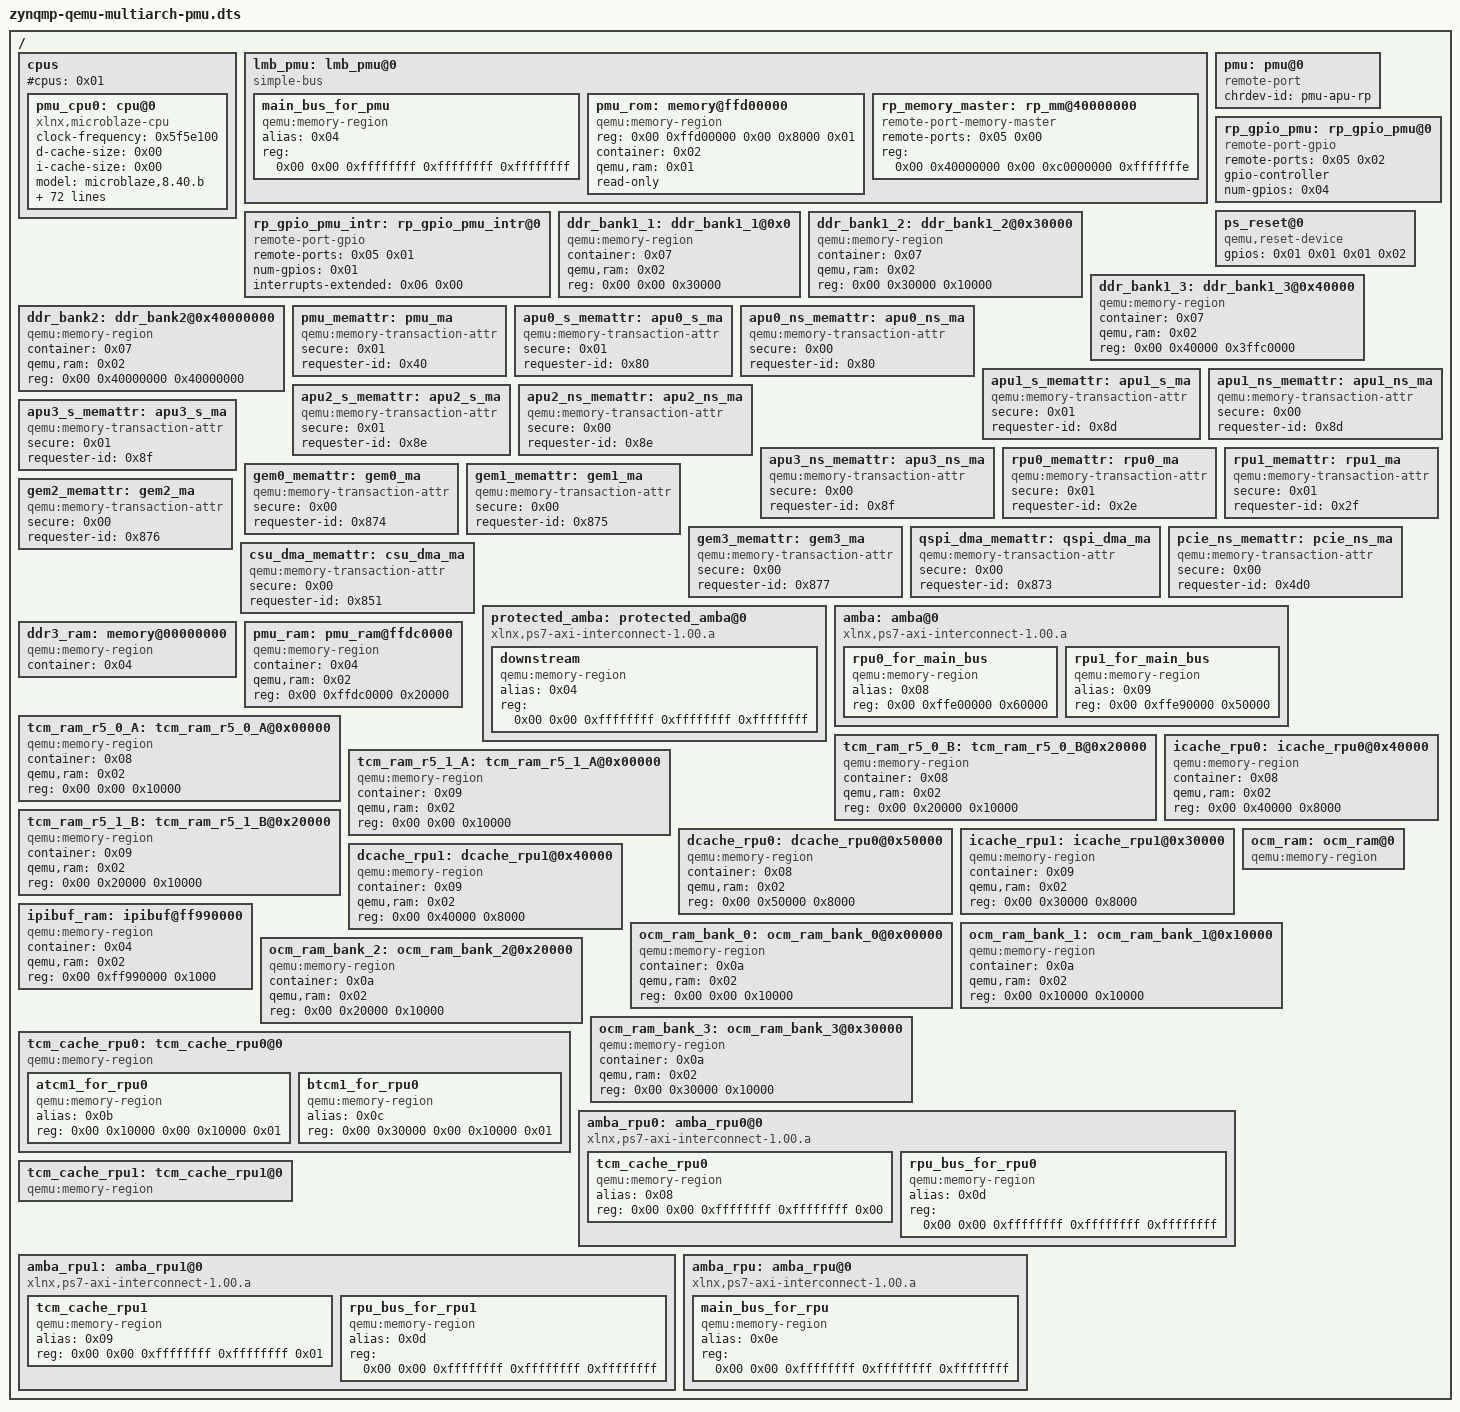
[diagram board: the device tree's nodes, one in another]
/dts-v1/;

/ {
	#address-cells = < 0x02 >;
	#size-cells = < 0x01 >;

	cpus {
		#address-cells = < 0x01 >;
		#cpus = < 0x01 >;
		#size-cells = < 0x00 >;

		pmu_cpu0: cpu@0 {
			#interrupt-cells = < 0x01 >;
			clock-frequency = < 0x5f5e100 >;
			compatible = "xlnx,microblaze-cpu";
			d-cache-size = < 0x00 >;
			device_type = "cpu";
			i-cache-size = < 0x00 >;
			model = "microblaze,8.40.b";
			version = "8.40.b";
			reg = < 0x00 >;
			timebase-frequency = < 0x5f5e100 >;
			xlnx,addr-tag-bits = < 0x10 >;
			xlnx,area-optimized = < 0x00 >;
			xlnx,avoid-primitives = < 0x03 >;
			xlnx,base-vectors = < 0xffd00000 >;
			xlnx,branch-target-cache-size = < 0x00 >;
			xlnx,d-axi = < 0x01 >;
			xlnx,d-lmb = < 0x01 >;
			xlnx,d-plb = < 0x00 >;
			xlnx,data-size = < 0x20 >;
			xlnx,debug-enabled = < 0x01 >;
			xlnx,div-zero-exception = < 0x00 >;
			xlnx,dynamic-bus-sizing = < 0x01 >;
			xlnx,ecc-use-ce-exception = < 0x00 >;
			xlnx,edge-is-positive = < 0x01 >;
			xlnx,endianness = < 0x01 >;
			xlnx,family = "virtex7";
			xlnx,fault-tolerant = < 0x01 >;
			xlnx,fpu-exception = < 0x00 >;
			xlnx,freq = < 0x5f5e100 >;
			xlnx,fsl-data-size = < 0x20 >;
			xlnx,fsl-exception = < 0x00 >;
			xlnx,fsl-links = < 0x00 >;
			xlnx,i-axi = < 0x01 >;
			xlnx,i-lmb = < 0x01 >;
			xlnx,i-plb = < 0x00 >;
			xlnx,ill-opcode-exception = < 0x01 >;
			xlnx,instance = "microblaze_1";
			xlnx,interconnect = < 0x02 >;
			xlnx,interrupt-is-edge = < 0x00 >;
			xlnx,lockstep-slave = < 0x00 >;
			xlnx,mmu-dtlb-size = < 0x02 >;
			xlnx,mmu-itlb-size = < 0x04 >;
			xlnx,mmu-privileged-instr = < 0x00 >;
			xlnx,mmu-tlb-access = < 0x03 >;
			xlnx,mmu-zones = < 0x02 >;
			xlnx,number-of-pc-brk = < 0x01 >;
			xlnx,number-of-rd-addr-brk = < 0x01 >;
			xlnx,number-of-wr-addr-brk = < 0x01 >;
			xlnx,opcode-0x0-illegal = < 0x01 >;
			xlnx,optimization = < 0x00 >;
			xlnx,pc-width = < 0x20 >;
			xlnx,pvr = < 0x00 >;
			xlnx,pvr-user1 = < 0x00 >;
			xlnx,pvr-user2 = < 0x00 >;
			xlnx,reset-msr = < 0x00 >;
			xlnx,sco = < 0x00 >;
			xlnx,stream-interconnect = < 0x00 >;
			xlnx,unaligned-exceptions = < 0x01 >;
			xlnx,use-barrel = < 0x01 >;
			xlnx,use-branch-target-cache = < 0x00 >;
			xlnx,use-dcache = < 0x00 >;
			xlnx,use-div = < 0x00 >;
			xlnx,use-ext-brk = < 0x01 >;
			xlnx,use-ext-nm-brk = < 0x01 >;
			xlnx,use-extended-fsl-instr = < 0x00 >;
			xlnx,use-fpu = < 0x00 >;
			xlnx,use-hw-mul = < 0x00 >;
			xlnx,use-icache = < 0x00 >;
			xlnx,use-interrupt = < 0x01 >;
			xlnx,use-mmu = < 0x00 >;
			xlnx,use-msr-instr = < 0x01 >;
			xlnx,use-pcmp-instr = < 0x01 >;
			xlnx,use-reorder-instr = < 0x01 >;
			xlnx,use-stack-protection = < 0x01 >;
			gpios = < 0x01 0x00 0x01 0x03 >;
			gpio-names = "wakeup", "mb_sleep";
			mr = < 0x02 >;
			memory = < 0x02 >;
			memattr = < 0x03 >;
			phandle = < 0x06 >;
		};
	};

	lmb_pmu: lmb_pmu@0 {
		#address-cells = < 0x02 >;
		#size-cells = < 0x02 >;
		#priority-cells = < 0x01 >;
		compatible = "simple-bus";
		ranges;
		phandle = < 0x02 >;

		main_bus_for_pmu {
			compatible = "qemu:memory-region";
			alias = < 0x04 >;
			reg = < 0x00 0x00 0xffffffff 0xffffffff 0xffffffff >;
		};

		pmu_rom: memory@ffd00000 {
			device_type = "memory";
			reg = < 0x00 0xffd00000 0x00 0x8000 0x01 >;
			compatible = "qemu:memory-region";
			container = < 0x02 >;
			qemu,ram = < 0x01 >;
			read-only;
		};

		rp_memory_master: rp_mm@40000000 {
			compatible = "remote-port-memory-master";
			remote-ports = < 0x05 0x00 >;
			reg = < 0x00 0x40000000 0x00 0xc0000000 0xfffffffe >;
		};
	};

	pmu: pmu@0 {
		compatible = "remote-port";
		chrdev-id = "pmu-apu-rp";
		phandle = < 0x05 >;
	};

	rp_gpio_pmu_intr: rp_gpio_pmu_intr@0 {
		compatible = "remote-port-gpio";
		remote-ports = < 0x05 0x01 >;
		num-gpios = < 0x01 >;
		interrupts-extended = < 0x06 0x00 >;
	};

	rp_gpio_pmu: rp_gpio_pmu@0 {
		#gpio-cells = < 0x01 >;
		compatible = "remote-port-gpio";
		remote-ports = < 0x05 0x02 >;
		gpio-controller;
		num-gpios = < 0x04 >;
		phandle = < 0x01 >;
	};

	ps_reset@0 {
		compatible = "qemu,reset-device";
		gpios = < 0x01 0x01 0x01 0x02 >;
	};

	ddr_bank1_1: ddr_bank1_1@0x0 {
		compatible = "qemu:memory-region";
		container = < 0x07 >;
		qemu,ram = < 0x02 >;
		reg = < 0x00 0x00 0x30000 >;
	};

	ddr_bank1_2: ddr_bank1_2@0x30000 {
		compatible = "qemu:memory-region";
		container = < 0x07 >;
		qemu,ram = < 0x02 >;
		reg = < 0x00 0x30000 0x10000 >;
	};

	ddr_bank1_3: ddr_bank1_3@0x40000 {
		compatible = "qemu:memory-region";
		container = < 0x07 >;
		qemu,ram = < 0x02 >;
		reg = < 0x00 0x40000 0x3ffc0000 >;
	};

	ddr_bank2: ddr_bank2@0x40000000 {
		compatible = "qemu:memory-region";
		container = < 0x07 >;
		qemu,ram = < 0x02 >;
		reg = < 0x00 0x40000000 0x40000000 >;
	};

	pmu_memattr: pmu_ma {
		compatible = "qemu:memory-transaction-attr";
		secure = < 0x01 >;
		requester-id = < 0x40 >;
		phandle = < 0x03 >;
	};

	apu0_s_memattr: apu0_s_ma {
		compatible = "qemu:memory-transaction-attr";
		secure = < 0x01 >;
		requester-id = < 0x80 >;
	};

	apu0_ns_memattr: apu0_ns_ma {
		compatible = "qemu:memory-transaction-attr";
		secure = < 0x00 >;
		requester-id = < 0x80 >;
	};

	apu1_s_memattr: apu1_s_ma {
		compatible = "qemu:memory-transaction-attr";
		secure = < 0x01 >;
		requester-id = < 0x8d >;
	};

	apu1_ns_memattr: apu1_ns_ma {
		compatible = "qemu:memory-transaction-attr";
		secure = < 0x00 >;
		requester-id = < 0x8d >;
	};

	apu2_s_memattr: apu2_s_ma {
		compatible = "qemu:memory-transaction-attr";
		secure = < 0x01 >;
		requester-id = < 0x8e >;
	};

	apu2_ns_memattr: apu2_ns_ma {
		compatible = "qemu:memory-transaction-attr";
		secure = < 0x00 >;
		requester-id = < 0x8e >;
	};

	apu3_s_memattr: apu3_s_ma {
		compatible = "qemu:memory-transaction-attr";
		secure = < 0x01 >;
		requester-id = < 0x8f >;
	};

	apu3_ns_memattr: apu3_ns_ma {
		compatible = "qemu:memory-transaction-attr";
		secure = < 0x00 >;
		requester-id = < 0x8f >;
	};

	rpu0_memattr: rpu0_ma {
		compatible = "qemu:memory-transaction-attr";
		secure = < 0x01 >;
		requester-id = < 0x2e >;
	};

	rpu1_memattr: rpu1_ma {
		compatible = "qemu:memory-transaction-attr";
		secure = < 0x01 >;
		requester-id = < 0x2f >;
	};

	gem0_memattr: gem0_ma {
		compatible = "qemu:memory-transaction-attr";
		secure = < 0x00 >;
		requester-id = < 0x874 >;
	};

	gem1_memattr: gem1_ma {
		compatible = "qemu:memory-transaction-attr";
		secure = < 0x00 >;
		requester-id = < 0x875 >;
	};

	gem2_memattr: gem2_ma {
		compatible = "qemu:memory-transaction-attr";
		secure = < 0x00 >;
		requester-id = < 0x876 >;
	};

	gem3_memattr: gem3_ma {
		compatible = "qemu:memory-transaction-attr";
		secure = < 0x00 >;
		requester-id = < 0x877 >;
	};

	qspi_dma_memattr: qspi_dma_ma {
		compatible = "qemu:memory-transaction-attr";
		secure = < 0x00 >;
		requester-id = < 0x873 >;
	};

	pcie_ns_memattr: pcie_ns_ma {
		compatible = "qemu:memory-transaction-attr";
		secure = < 0x00 >;
		requester-id = < 0x4d0 >;
	};

	csu_dma_memattr: csu_dma_ma {
		compatible = "qemu:memory-transaction-attr";
		secure = < 0x00 >;
		requester-id = < 0x851 >;
	};

	protected_amba: protected_amba@0 {
		#address-cells = < 0x02 >;
		#size-cells = < 0x02 >;
		#priority-cells = < 0x01 >;
		compatible = "xlnx,ps7-axi-interconnect-1.00.a", "simple-bus";
		ranges;
		phandle = < 0x0e >;

		downstream {
			compatible = "qemu:memory-region";
			alias = < 0x04 >;
			reg = < 0x00 0x00 0xffffffff 0xffffffff 0xffffffff >;
		};
	};

	amba: amba@0 {
		#address-cells = < 0x02 >;
		#size-cells = < 0x01 >;
		compatible = "xlnx,ps7-axi-interconnect-1.00.a", "simple-bus";
		ranges;
		phandle = < 0x04 >;

		rpu0_for_main_bus {
			compatible = "qemu:memory-region";
			alias = < 0x08 >;
			reg = < 0x00 0xffe00000 0x60000 >;
		};

		rpu1_for_main_bus {
			compatible = "qemu:memory-region";
			alias = < 0x09 >;
			reg = < 0x00 0xffe90000 0x50000 >;
		};
	};

	ddr3_ram: memory@00000000 {
		compatible = "qemu:memory-region";
		device_type = "memory";
		container = < 0x04 >;
		phandle = < 0x07 >;
	};

	pmu_ram: pmu_ram@ffdc0000 {
		compatible = "qemu:memory-region";
		container = < 0x04 >;
		qemu,ram = < 0x02 >;
		reg = < 0x00 0xffdc0000 0x20000 >;
	};

	tcm_ram_r5_0_A: tcm_ram_r5_0_A@0x00000 {
		compatible = "qemu:memory-region";
		container = < 0x08 >;
		qemu,ram = < 0x02 >;
		reg = < 0x00 0x00 0x10000 >;
	};

	tcm_ram_r5_0_B: tcm_ram_r5_0_B@0x20000 {
		compatible = "qemu:memory-region";
		container = < 0x08 >;
		qemu,ram = < 0x02 >;
		reg = < 0x00 0x20000 0x10000 >;
	};

	tcm_ram_r5_1_A: tcm_ram_r5_1_A@0x00000 {
		compatible = "qemu:memory-region";
		container = < 0x09 >;
		qemu,ram = < 0x02 >;
		reg = < 0x00 0x00 0x10000 >;
		phandle = < 0x0b >;
	};

	tcm_ram_r5_1_B: tcm_ram_r5_1_B@0x20000 {
		compatible = "qemu:memory-region";
		container = < 0x09 >;
		qemu,ram = < 0x02 >;
		reg = < 0x00 0x20000 0x10000 >;
		phandle = < 0x0c >;
	};

	icache_rpu0: icache_rpu0@0x40000 {
		compatible = "qemu:memory-region";
		container = < 0x08 >;
		qemu,ram = < 0x02 >;
		reg = < 0x00 0x40000 0x8000 >;
	};

	dcache_rpu0: dcache_rpu0@0x50000 {
		compatible = "qemu:memory-region";
		container = < 0x08 >;
		qemu,ram = < 0x02 >;
		reg = < 0x00 0x50000 0x8000 >;
	};

	icache_rpu1: icache_rpu1@0x30000 {
		compatible = "qemu:memory-region";
		container = < 0x09 >;
		qemu,ram = < 0x02 >;
		reg = < 0x00 0x30000 0x8000 >;
	};

	dcache_rpu1: dcache_rpu1@0x40000 {
		compatible = "qemu:memory-region";
		container = < 0x09 >;
		qemu,ram = < 0x02 >;
		reg = < 0x00 0x40000 0x8000 >;
	};

	ipibuf_ram: ipibuf@ff990000 {
		compatible = "qemu:memory-region";
		container = < 0x04 >;
		qemu,ram = < 0x02 >;
		reg = < 0x00 0xff990000 0x1000 >;
	};

	ocm_ram: ocm_ram@0 {
		compatible = "qemu:memory-region";
		phandle = < 0x0a >;
	};

	ocm_ram_bank_0: ocm_ram_bank_0@0x00000 {
		compatible = "qemu:memory-region";
		container = < 0x0a >;
		qemu,ram = < 0x02 >;
		reg = < 0x00 0x00 0x10000 >;
	};

	ocm_ram_bank_1: ocm_ram_bank_1@0x10000 {
		compatible = "qemu:memory-region";
		container = < 0x0a >;
		qemu,ram = < 0x02 >;
		reg = < 0x00 0x10000 0x10000 >;
	};

	ocm_ram_bank_2: ocm_ram_bank_2@0x20000 {
		compatible = "qemu:memory-region";
		container = < 0x0a >;
		qemu,ram = < 0x02 >;
		reg = < 0x00 0x20000 0x10000 >;
	};

	ocm_ram_bank_3: ocm_ram_bank_3@0x30000 {
		compatible = "qemu:memory-region";
		container = < 0x0a >;
		qemu,ram = < 0x02 >;
		reg = < 0x00 0x30000 0x10000 >;
	};

	tcm_cache_rpu0: tcm_cache_rpu0@0 {
		#address-cells = < 0x02 >;
		#size-cells = < 0x02 >;
		#priority-cells = < 0x01 >;
		compatible = "qemu:memory-region";
		phandle = < 0x08 >;

		atcm1_for_rpu0: atcm1_for_rpu0 {
			compatible = "qemu:memory-region";
			alias = < 0x0b >;
			reg = < 0x00 0x10000 0x00 0x10000 0x01 >;
		};

		btcm1_for_rpu0: btcm1_for_rpu0 {
			compatible = "qemu:memory-region";
			alias = < 0x0c >;
			reg = < 0x00 0x30000 0x00 0x10000 0x01 >;
		};
	};

	amba_rpu0: amba_rpu0@0 {
		#address-cells = < 0x02 >;
		#size-cells = < 0x02 >;
		#priority-cells = < 0x01 >;
		compatible = "xlnx,ps7-axi-interconnect-1.00.a", "simple-bus";
		ranges;

		tcm_cache_rpu0 {
			compatible = "qemu:memory-region";
			alias = < 0x08 >;
			reg = < 0x00 0x00 0xffffffff 0xffffffff 0x00 >;
		};

		rpu_bus_for_rpu0 {
			compatible = "qemu:memory-region";
			alias = < 0x0d >;
			reg = < 0x00 0x00 0xffffffff 0xffffffff 0xffffffff >;
		};
	};

	tcm_cache_rpu1: tcm_cache_rpu1@0 {
		#address-cells = < 0x02 >;
		#size-cells = < 0x02 >;
		#priority-cells = < 0x01 >;
		compatible = "qemu:memory-region";
		phandle = < 0x09 >;
	};

	amba_rpu1: amba_rpu1@0 {
		#address-cells = < 0x02 >;
		#size-cells = < 0x02 >;
		#priority-cells = < 0x01 >;
		compatible = "xlnx,ps7-axi-interconnect-1.00.a", "simple-bus";
		ranges;

		tcm_cache_rpu1 {
			compatible = "qemu:memory-region";
			alias = < 0x09 >;
			reg = < 0x00 0x00 0xffffffff 0xffffffff 0x01 >;
		};

		rpu_bus_for_rpu1 {
			compatible = "qemu:memory-region";
			alias = < 0x0d >;
			reg = < 0x00 0x00 0xffffffff 0xffffffff 0xffffffff >;
		};
	};

	amba_rpu: amba_rpu@0 {
		#address-cells = < 0x02 >;
		#size-cells = < 0x02 >;
		#priority-cells = < 0x01 >;
		compatible = "xlnx,ps7-axi-interconnect-1.00.a", "simple-bus";
		ranges;
		phandle = < 0x0d >;

		main_bus_for_rpu {
			compatible = "qemu:memory-region";
			alias = < 0x0e >;
			reg = < 0x00 0x00 0xffffffff 0xffffffff 0xffffffff >;
		};
	};
};
